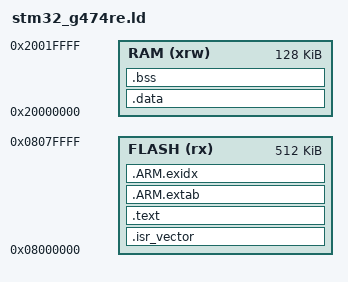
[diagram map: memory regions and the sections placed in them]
ENTRY(Reset_Handler)

MEMORY
{
  FLASH (rx)  : ORIGIN = 0x08000000, LENGTH = 512K
  RAM   (xrw) : ORIGIN = 0x20000000, LENGTH = 128K
}

_estack = ORIGIN(RAM) + LENGTH(RAM);

SECTIONS
{
  .isr_vector :
  {
    KEEP(*(.isr_vector))
  } > FLASH

  .text :
  {
    *(.text*)
    *(.rodata*)
    KEEP(*(.init))
    KEEP(*(.fini))
  } > FLASH

  .ARM.extab :
  {
    *(.ARM.extab* .gnu.linkonce.armextab.*)
  } > FLASH

  .ARM.exidx :
  {
    __exidx_start = .;
    *(.ARM.exidx* .gnu.linkonce.armexidx.*)
    __exidx_end = .;
  } > FLASH

  _etext = .;
  _sidata = LOADADDR(.data);

  .data : AT(_etext)
  {
    _sdata = .;
    *(.data*)
    _edata = .;
  } > RAM

  .bss :
  {
    _sbss = .;
    *(.bss*)
    *(COMMON)
    _ebss = .;
  } > RAM

  /DISCARD/ :
  {
    *(.note*)
    *(.comment*)
  }
}
